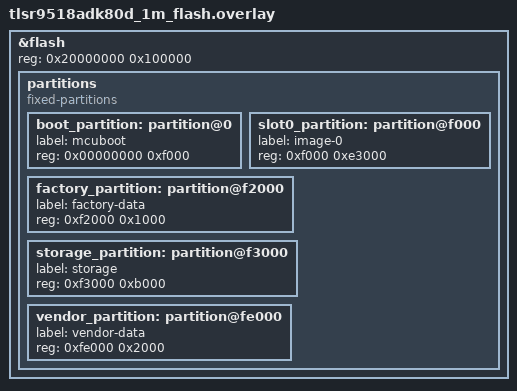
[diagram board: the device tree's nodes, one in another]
&flash {
	reg = <0x20000000 0x100000>;

	/delete-node/ partitions;
	partitions {
		compatible = "fixed-partitions";
		#address-cells = <1>;
		#size-cells = <1>;

		boot_partition: partition@0 {
			label = "mcuboot";
			reg = <0x00000000 0xf000>;
		};
		slot0_partition: partition@f000 {
			label = "image-0";
			reg = <0xf000 0xe3000>;
		};
		factory_partition: partition@f2000 {
			label = "factory-data";
			reg = <0xf2000 0x1000>;
		};
		storage_partition: partition@f3000 {
			label = "storage";
			reg = <0xf3000 0xb000>;
		};
		vendor_partition: partition@fe000 {
			label = "vendor-data";
			reg = <0xfe000 0x2000>;
		};
	};
};
